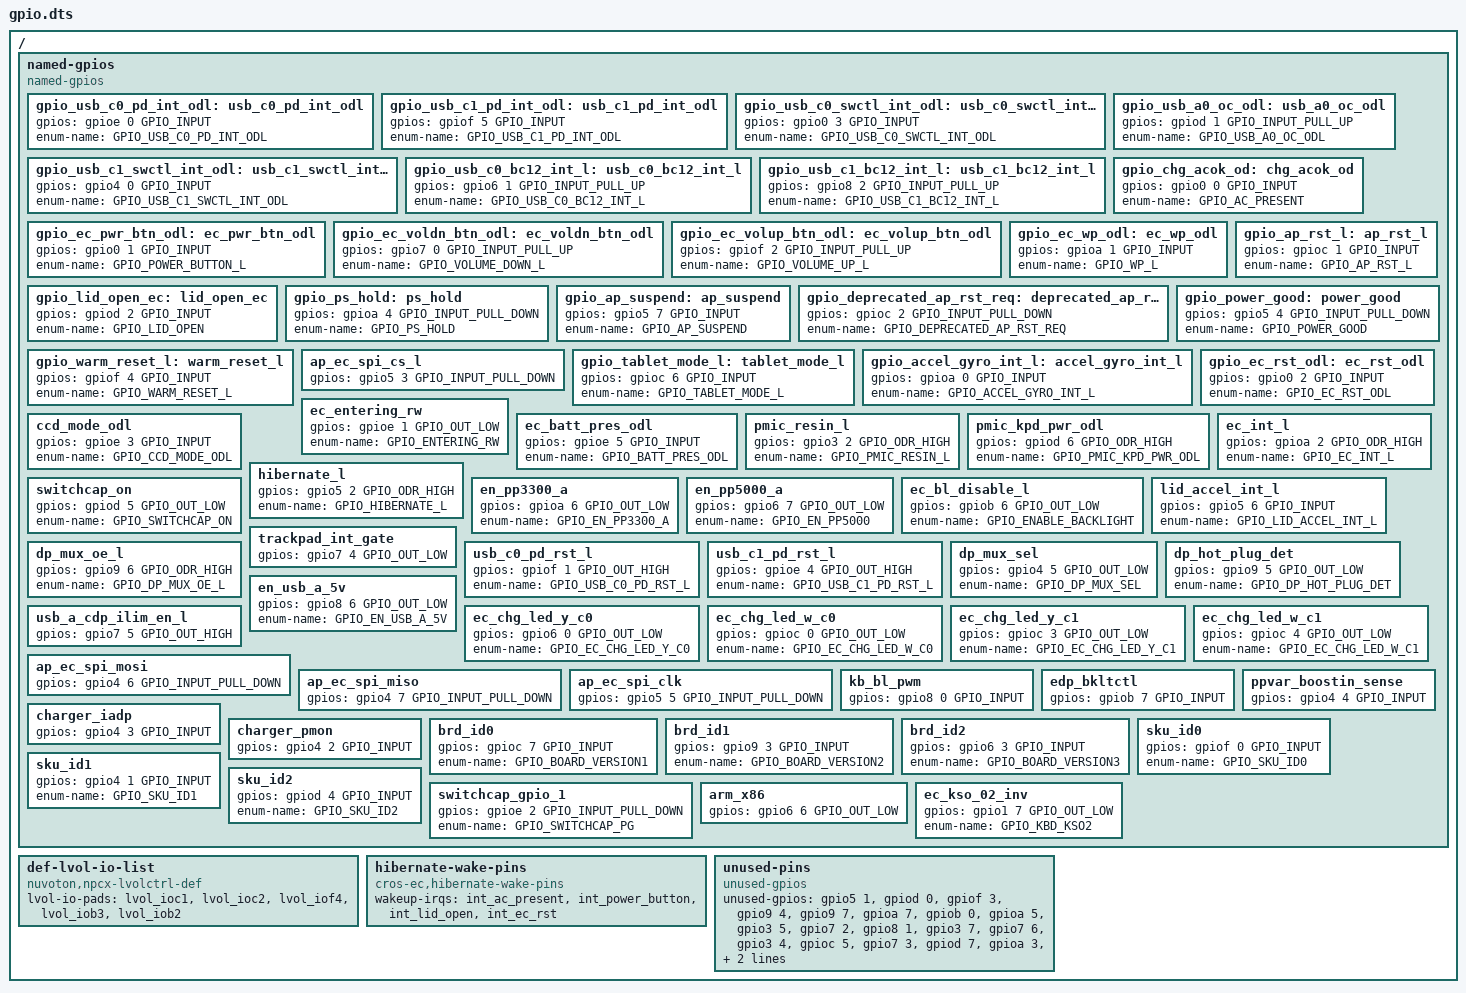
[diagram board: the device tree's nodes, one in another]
/* Copyright 2021 The Chromium OS Authors. All rights reserved.
 * Use of this source code is governed by a BSD-style license that can be
 * found in the LICENSE file.
 */

/ {
	named-gpios {
		compatible = "named-gpios";

		gpio_usb_c0_pd_int_odl: usb_c0_pd_int_odl {
			gpios = <&gpioe 0 GPIO_INPUT>;
			enum-name = "GPIO_USB_C0_PD_INT_ODL";
		};
		gpio_usb_c1_pd_int_odl: usb_c1_pd_int_odl {
			gpios = <&gpiof 5 GPIO_INPUT>;
			enum-name = "GPIO_USB_C1_PD_INT_ODL";
		};
		gpio_usb_c0_swctl_int_odl: usb_c0_swctl_int_odl {
			gpios = <&gpio0 3 GPIO_INPUT>;
			enum-name = "GPIO_USB_C0_SWCTL_INT_ODL";
		};
		gpio_usb_c1_swctl_int_odl: usb_c1_swctl_int_odl {
			gpios = <&gpio4 0 GPIO_INPUT>;
			enum-name = "GPIO_USB_C1_SWCTL_INT_ODL";
		};
		gpio_usb_c0_bc12_int_l: usb_c0_bc12_int_l {
			gpios = <&gpio6 1 GPIO_INPUT_PULL_UP>;
			enum-name = "GPIO_USB_C0_BC12_INT_L";
		};
		gpio_usb_c1_bc12_int_l: usb_c1_bc12_int_l {
			gpios = <&gpio8 2 GPIO_INPUT_PULL_UP>;
			enum-name = "GPIO_USB_C1_BC12_INT_L";
		};
		gpio_usb_a0_oc_odl: usb_a0_oc_odl {
			gpios = <&gpiod 1 GPIO_INPUT_PULL_UP>;
			enum-name = "GPIO_USB_A0_OC_ODL";
		};
		gpio_chg_acok_od: chg_acok_od {
			gpios = <&gpio0 0 GPIO_INPUT>;
			enum-name = "GPIO_AC_PRESENT";
		};
		gpio_ec_pwr_btn_odl: ec_pwr_btn_odl {
			gpios = <&gpio0 1 GPIO_INPUT>;
			enum-name = "GPIO_POWER_BUTTON_L";
		};
		gpio_ec_voldn_btn_odl: ec_voldn_btn_odl {
			gpios = <&gpio7 0 GPIO_INPUT_PULL_UP>;
			enum-name = "GPIO_VOLUME_DOWN_L";
		};
		gpio_ec_volup_btn_odl: ec_volup_btn_odl {
			gpios = <&gpiof 2 GPIO_INPUT_PULL_UP>;
			enum-name = "GPIO_VOLUME_UP_L";
		};
		gpio_ec_wp_odl: ec_wp_odl {
			gpios = <&gpioa 1 GPIO_INPUT>;
			enum-name = "GPIO_WP_L";
		};
		gpio_lid_open_ec: lid_open_ec {
			gpios = <&gpiod 2 GPIO_INPUT>;
			enum-name = "GPIO_LID_OPEN";
		};
		gpio_ap_rst_l: ap_rst_l {
			gpios = <&gpioc 1 GPIO_INPUT>;
			enum-name = "GPIO_AP_RST_L";
		};
		gpio_ps_hold: ps_hold {
			gpios = <&gpioa 4 GPIO_INPUT_PULL_DOWN>;
			enum-name = "GPIO_PS_HOLD";
		};
		gpio_ap_suspend: ap_suspend {
			gpios = <&gpio5 7 GPIO_INPUT>;
			enum-name = "GPIO_AP_SUSPEND";
		};
		gpio_deprecated_ap_rst_req: deprecated_ap_rst_req {
			gpios = <&gpioc 2 GPIO_INPUT_PULL_DOWN>;
			enum-name = "GPIO_DEPRECATED_AP_RST_REQ";
		};
		gpio_power_good: power_good {
			gpios = <&gpio5 4 GPIO_INPUT_PULL_DOWN>;
			enum-name = "GPIO_POWER_GOOD";
		};
		gpio_warm_reset_l: warm_reset_l {
			gpios = <&gpiof 4 GPIO_INPUT>;
			enum-name = "GPIO_WARM_RESET_L";
		};
		ap_ec_spi_cs_l {
			gpios = <&gpio5 3 GPIO_INPUT_PULL_DOWN>;
		};
		gpio_tablet_mode_l: tablet_mode_l {
			gpios = <&gpioc 6 GPIO_INPUT>;
			enum-name = "GPIO_TABLET_MODE_L";
		};
		gpio_accel_gyro_int_l: accel_gyro_int_l {
			gpios = <&gpioa 0 GPIO_INPUT>;
			enum-name = "GPIO_ACCEL_GYRO_INT_L";
		};
		gpio_ec_rst_odl: ec_rst_odl {
			gpios = <&gpio0 2 GPIO_INPUT>;
			enum-name = "GPIO_EC_RST_ODL";
		};
		ec_entering_rw {
			gpios = <&gpioe 1 GPIO_OUT_LOW>;
			enum-name = "GPIO_ENTERING_RW";
		};
		ccd_mode_odl {
			gpios = <&gpioe 3 GPIO_INPUT>;
			enum-name = "GPIO_CCD_MODE_ODL";
		};
		ec_batt_pres_odl {
			gpios = <&gpioe 5 GPIO_INPUT>;
			enum-name = "GPIO_BATT_PRES_ODL";
		};
		pmic_resin_l {
			gpios = <&gpio3 2 GPIO_ODR_HIGH>;
			enum-name = "GPIO_PMIC_RESIN_L";
		};
		pmic_kpd_pwr_odl {
			gpios = <&gpiod 6 GPIO_ODR_HIGH>;
			enum-name = "GPIO_PMIC_KPD_PWR_ODL";
		};
		ec_int_l {
			gpios = <&gpioa 2 GPIO_ODR_HIGH>;
			enum-name = "GPIO_EC_INT_L";
		};
		hibernate_l {
			gpios = <&gpio5 2 GPIO_ODR_HIGH>;
			enum-name = "GPIO_HIBERNATE_L";
		};
		switchcap_on {
			gpios = <&gpiod 5 GPIO_OUT_LOW>;
			enum-name = "GPIO_SWITCHCAP_ON";
		};
		en_pp3300_a {
			gpios = <&gpioa 6 GPIO_OUT_LOW>;
			enum-name = "GPIO_EN_PP3300_A";
		};
		en_pp5000_a {
			gpios = <&gpio6 7 GPIO_OUT_LOW>;
			enum-name = "GPIO_EN_PP5000";
		};
		ec_bl_disable_l {
			gpios = <&gpiob 6 GPIO_OUT_LOW>;
			enum-name = "GPIO_ENABLE_BACKLIGHT";
		};
		lid_accel_int_l {
			gpios = <&gpio5 6 GPIO_INPUT>;
			enum-name = "GPIO_LID_ACCEL_INT_L";
		};
		trackpad_int_gate {
			gpios = <&gpio7 4 GPIO_OUT_LOW>;
		};
		usb_c0_pd_rst_l {
			gpios = <&gpiof 1 GPIO_OUT_HIGH>;
			enum-name = "GPIO_USB_C0_PD_RST_L";
		};
		usb_c1_pd_rst_l {
			gpios = <&gpioe 4 GPIO_OUT_HIGH>;
			enum-name = "GPIO_USB_C1_PD_RST_L";
		};
		dp_mux_oe_l {
			gpios = <&gpio9 6 GPIO_ODR_HIGH>;
			enum-name = "GPIO_DP_MUX_OE_L";
		};
		dp_mux_sel {
			gpios = <&gpio4 5 GPIO_OUT_LOW>;
			enum-name = "GPIO_DP_MUX_SEL";
		};
		dp_hot_plug_det {
			gpios = <&gpio9 5 GPIO_OUT_LOW>;
			enum-name = "GPIO_DP_HOT_PLUG_DET";
		};
		en_usb_a_5v {
			gpios = <&gpio8 6 GPIO_OUT_LOW>;
			enum-name = "GPIO_EN_USB_A_5V";
		};
		usb_a_cdp_ilim_en_l {
			gpios = <&gpio7 5 GPIO_OUT_HIGH>;
		};
		ec_chg_led_y_c0 {
			gpios = <&gpio6 0 GPIO_OUT_LOW>;
			enum-name = "GPIO_EC_CHG_LED_Y_C0";
		};
		ec_chg_led_w_c0 {
			gpios = <&gpioc 0 GPIO_OUT_LOW>;
			enum-name = "GPIO_EC_CHG_LED_W_C0";
		};
		ec_chg_led_y_c1 {
			gpios = <&gpioc 3 GPIO_OUT_LOW>;
			enum-name = "GPIO_EC_CHG_LED_Y_C1";
		};
		ec_chg_led_w_c1 {
			gpios = <&gpioc 4 GPIO_OUT_LOW>;
			enum-name = "GPIO_EC_CHG_LED_W_C1";
		};
		ap_ec_spi_mosi {
			gpios = <&gpio4 6 GPIO_INPUT_PULL_DOWN>;
		};
		ap_ec_spi_miso {
			gpios = <&gpio4 7 GPIO_INPUT_PULL_DOWN>;
		};
		ap_ec_spi_clk {
			gpios = <&gpio5 5 GPIO_INPUT_PULL_DOWN>;
		};
		kb_bl_pwm {
			gpios = <&gpio8 0 GPIO_INPUT>;
		};
		edp_bkltctl {
			gpios = <&gpiob 7 GPIO_INPUT>;
		};
		ppvar_boostin_sense {
			gpios = <&gpio4 4 GPIO_INPUT>;
		};
		charger_iadp {
			gpios = <&gpio4 3 GPIO_INPUT>;
		};
		charger_pmon {
			gpios = <&gpio4 2 GPIO_INPUT>;
		};
		brd_id0 {
			gpios = <&gpioc 7 GPIO_INPUT>;
			enum-name = "GPIO_BOARD_VERSION1";
		};
		brd_id1 {
			gpios = <&gpio9 3 GPIO_INPUT>;
			enum-name = "GPIO_BOARD_VERSION2";
		};
		brd_id2 {
			gpios = <&gpio6 3 GPIO_INPUT>;
			enum-name = "GPIO_BOARD_VERSION3";
		};
		sku_id0 {
			gpios = <&gpiof 0 GPIO_INPUT>;
			enum-name = "GPIO_SKU_ID0";
		};
		sku_id1 {
			gpios = <&gpio4 1 GPIO_INPUT>;
			enum-name = "GPIO_SKU_ID1";
		};
		sku_id2 {
			gpios = <&gpiod 4 GPIO_INPUT>;
			enum-name = "GPIO_SKU_ID2";
		};
		switchcap_gpio_1 {
			gpios = <&gpioe 2 GPIO_INPUT_PULL_DOWN>;
			enum-name = "GPIO_SWITCHCAP_PG";
		};
		arm_x86 {
			gpios = <&gpio6 6 GPIO_OUT_LOW>;
		};
		ec_kso_02_inv {
			gpios = <&gpio1 7 GPIO_OUT_LOW>;
			enum-name = "GPIO_KBD_KSO2";
		};
	};

	def-lvol-io-list {
		compatible = "nuvoton,npcx-lvolctrl-def";
		lvol-io-pads = <
			&lvol_ioc1 /* AP_RST_L */
			&lvol_ioc2 /* DEPRECATED_AP_RST_REQ */
			&lvol_iof4 /* WARM_RESET_L */
			&lvol_iob3 /* EC_I2C_SENSOR_SCL */
			&lvol_iob2 /* EC_I2C_SENSOR_SDA */
		>;
	};

	hibernate-wake-pins {
		compatible = "cros-ec,hibernate-wake-pins";
		wakeup-irqs = <
			&int_ac_present
			&int_power_button
			&int_lid_open
			&int_ec_rst
		>;
	};

	unused-pins {
		compatible = "unused-gpios";
		unused-gpios =
			<&gpio5 1 0>,
			<&gpiod 0 0>,
			<&gpiof 3 0>,
			<&gpio9 4 0>,
			<&gpio9 7 0>,
			<&gpioa 7 0>,
			<&gpiob 0 0>,
			<&gpioa 5 0>,
			<&gpio3 5 0>,
			<&gpio7 2 0>,
			<&gpio8 1 0>,
			<&gpio3 7 0>,
			<&gpio7 6 0>,
			<&gpio3 4 0>,
			<&gpioc 5 0>,
			<&gpio7 3 0>,
			<&gpiod 7 0>,
			<&gpioa 3 0>,
			<&gpio6 2 0>,
			<&gpio0 4 0>,
			<&gpio8 3 0>,
			<&gpiob 1 0>,
			<&gpio5 0 0>,
			<&gpiod 3 0>;
	};
};
